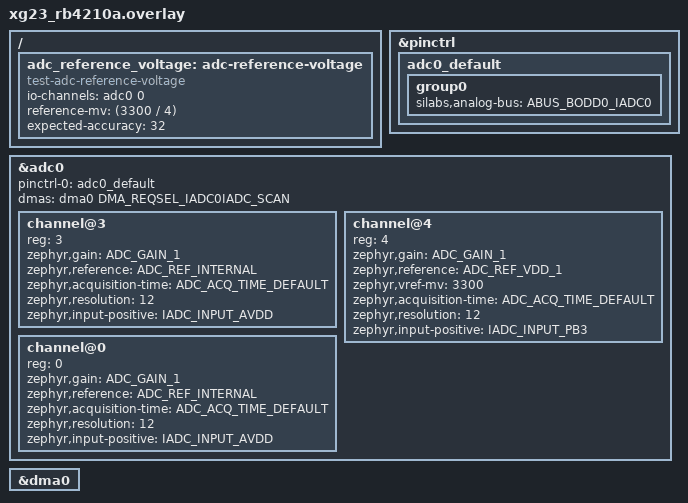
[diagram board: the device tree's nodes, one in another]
/*
 * SPDX-License-Identifier: Apache-2.0
 *
 * Copyright (c) 2025 Silicon Laboratories Inc.
 */

#include <zephyr/dt-bindings/adc/silabs-adc.h>

&pinctrl {
	adc0_default: adc0_default {
		group0 {
			/* Allocate odd bus 0 on GPIO port B to IADC for access to pin PB1 */
			silabs,analog-bus = <ABUS_BODD0_IADC0>;
		};
	};
};

&adc0 {
	pinctrl-0 = <&adc0_default>;
	pinctrl-names = "default";
	#address-cells = <1>;
	#size-cells = <0>;
	status = "okay";

	channel@3 {
		reg = <3>;
		zephyr,gain = "ADC_GAIN_1";
		zephyr,reference = "ADC_REF_INTERNAL";
		zephyr,acquisition-time = <ADC_ACQ_TIME_DEFAULT>;
		zephyr,resolution = <12>;
		zephyr,input-positive = <IADC_INPUT_AVDD>;
	};

	channel@4 {
		reg = <4>;
		zephyr,gain = "ADC_GAIN_1";
		zephyr,reference = "ADC_REF_VDD_1";
		zephyr,vref-mv = <3300>;
		zephyr,acquisition-time = <ADC_ACQ_TIME_DEFAULT>;
		zephyr,resolution = <12>;
		zephyr,input-positive = <IADC_INPUT_PB3>;
	};

	channel@0 {
		reg = <0>;
		zephyr,gain = "ADC_GAIN_1";
		zephyr,reference = "ADC_REF_INTERNAL";
		zephyr,acquisition-time = <ADC_ACQ_TIME_DEFAULT>;
		zephyr,resolution = <12>;
		zephyr,input-positive = <IADC_INPUT_AVDD>;
	};
};

&adc0 {
	dmas = <&dma0 DMA_REQSEL_IADC0IADC_SCAN>;
};

&dma0 {
	status = "okay";
};

/ {
	adc_reference_voltage: adc-reference-voltage {
		compatible = "test-adc-reference-voltage";
		io-channels = <&adc0 0>;
		reference-mv = <(3300 / 4)>;
		expected-accuracy = <32>;
	};
};
